CM_ "IMPORT _toyota_2017.dbc"
CM_ "IMPORT _comma.dbc"

BO_ 295 GEAR_PACKET2: 8 XXX
 SG_ CAR_MOVEMENT : 39|8@0- (1,0) [0|255] "" XX

BO_ 548 BRAKE_MODULE: 8 XXX
 SG_ BRAKE_PRESSURE : 47|8@0+ (1,0) [0|255] "" XXX

BO_ 581 GAS_PEDAL: 8 XXX
 SG_ GAS_PEDAL : 23|8@0+ (0.005,0) [0|1] "" XXX

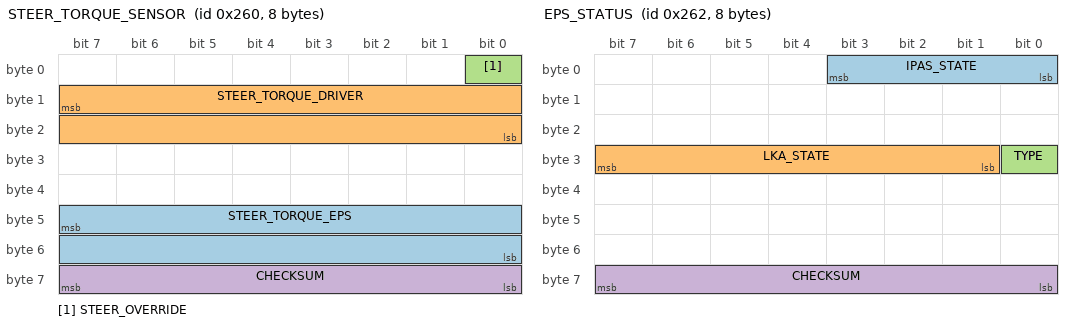
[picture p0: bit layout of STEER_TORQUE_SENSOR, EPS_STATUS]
BO_ 608 STEER_TORQUE_SENSOR: 8 XXX
 SG_ STEER_TORQUE_EPS : 47|16@0- (0.73,0) [-20000|20000] "" XXX
 SG_ STEER_TORQUE_DRIVER : 15|16@0- (1,0) [-32768|32767] "" XXX
 SG_ STEER_OVERRIDE : 0|1@0+ (1,0) [0|1] "" XXX
 SG_ CHECKSUM : 63|8@0+ (1,0) [0|255] "" XXX

BO_ 610 EPS_STATUS: 8 EPS
 SG_ IPAS_STATE : 3|4@0+ (1,0) [0|15] "" XXX
 SG_ LKA_STATE : 31|7@0+ (1,0) [0|127] "" XXX
 SG_ TYPE : 24|1@0+ (1,0) [0|1] "" XXX
 SG_ CHECKSUM : 63|8@0+ (1,0) [0|255] "" XXX

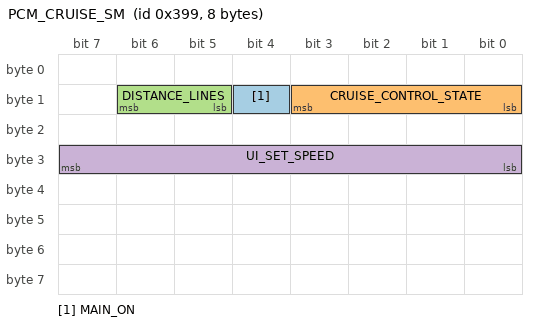
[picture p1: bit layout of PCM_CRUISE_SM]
BO_ 921 PCM_CRUISE_SM: 8 XXX
 SG_ MAIN_ON : 12|1@0+ (1,0) [0|1] "" XXX
 SG_ CRUISE_CONTROL_STATE : 11|4@0+ (1,0) [0|15] "" XXX
 SG_ DISTANCE_LINES : 14|2@0+ (1,0) [0|3] "" XXX
 SG_ UI_SET_SPEED : 31|8@0+ (1,0) [0|255] "" XXX

BO_ 956 GEAR_PACKET: 8 XXX
 SG_ GEAR : 13|6@0+ (1,0) [0|63] "" XXX
 SG_ SPORT_ON : 3|1@0+ (1,0) [0|1] "" XXX

CM_ SG_ 921 UI_SET_SPEED "set speed shown in UI with user set unit";
2CM_ SG_ 581 GAS_PEDAL "it seems slightly filtered";
VAL_ 921 CRUISE_CONTROL_STATE 0 "disabled" 2 "enabled";
VAL_ 956 GEAR 0 "D" 1 "S" 8 "N" 16 "R" 32 "P";
